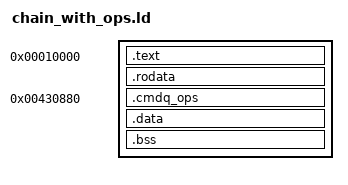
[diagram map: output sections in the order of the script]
ENTRY(opencfw_bl_mspi_enable)
SECTIONS {
  . = 0x10000;
  .text : { *(.text*) }
  .rodata : { *(.rodata*) }
  .cmdq_ops 0x430880 : { KEEP(*(.cmdq_ops)) }
  .data : { *(.data*) }
  .bss : { *(.bss*) }
  /DISCARD/ : { *(.ARM.exidx*) *(.ARM.extab*) *(.comment*) }
}
